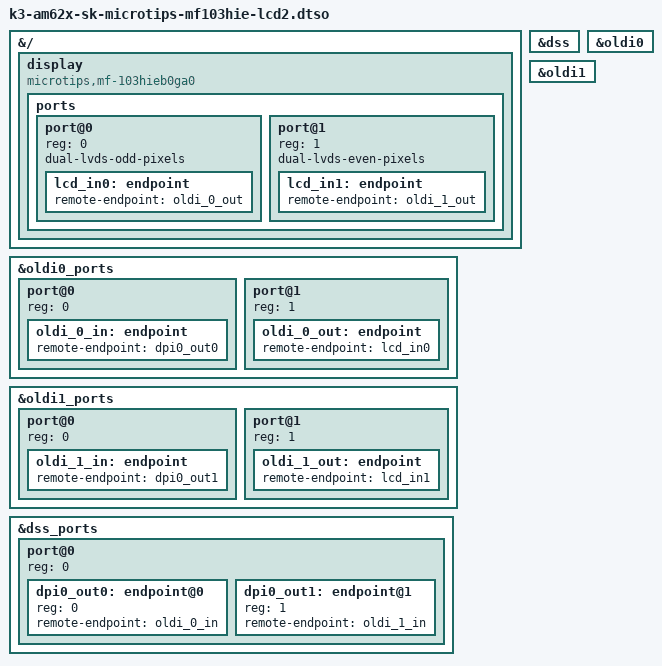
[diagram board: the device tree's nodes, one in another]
// SPDX-License-Identifier: GPL-2.0-or-later OR MIT
/**
 * Microtips integrated OLDI panel (MF-103HIEB0GA0) (SK-LCD2) DT overlay for AM625-SK and AM62-LP SK
 *
 * AM625-SKEVM: https://www.ti.com/tool/SK-AM62
 * AM62-LP SKEVM: https://www.ti.com/tool/SK-AM62-LP
 * Panel datasheet: https://simplespec.microtipsusa.com/uploads/spec/datasheetFile/2660/13-103HIEB0GA0-S_V1.0_20211206.pdf
 *
 * Copyright (C) 2024 Texas Instruments Incorporated - http://www.ti.com/
 */

/dts-v1/;
/plugin/;

#include <dt-bindings/gpio/gpio.h>
#include <dt-bindings/interrupt-controller/irq.h>

&{/} {
	display {
		compatible = "microtips,mf-103hieb0ga0", "panel-simple";
		/*
		* Note that the OLDI TX 0 transmits the odd set of pixels
		* while the OLDI TX 1 transmits the even set. This is a
		* fixed configuration in the IP integration and is not
		* changeable. The properties, "dual-lvds-odd-pixels" and
		* "dual-lvds-even-pixels" have been used to merely
		* identify if a Dual Link configuration is required.
		* Swapping them will cause an error in the dss oldi driver.
		*/
		ports {
			#address-cells = <1>;
			#size-cells = <0>;

			port@0 {
				reg = <0>;
				dual-lvds-odd-pixels;
				lcd_in0: endpoint {
					remote-endpoint = <&oldi_0_out>;
				};
			};
			port@1 {
				reg = <1>;
				dual-lvds-even-pixels;
				lcd_in1: endpoint {
					remote-endpoint = <&oldi_1_out>;
				};
			};
		};
	};
};

&dss {
	status = "okay";
};

&oldi0 {
	status = "okay";
};

&oldi1 {
	status = "okay";
};

&oldi0_ports {
	#address-cells = <1>;
	#size-cells = <0>;

	port@0 {
		reg = <0>;
		oldi_0_in: endpoint {
			remote-endpoint = <&dpi0_out0>;
		};
	};

	port@1 {
		reg = <1>;
		oldi_0_out: endpoint {
			remote-endpoint = <&lcd_in0>;
		};
	};
};

&oldi1_ports {
	#address-cells = <1>;
	#size-cells = <0>;

	port@0 {
		reg = <0>;
		oldi_1_in: endpoint {
			remote-endpoint = <&dpi0_out1>;
		};
	};

	port@1 {
		reg = <1>;
		oldi_1_out: endpoint {
			remote-endpoint = <&lcd_in1>;
		};
	};
};

&dss_ports {
	#address-cells = <1>;
	#size-cells = <0>;

	/* VP1: Output to OLDI */
	port@0 {
		reg = <0>;
		#address-cells = <1>;
		#size-cells = <0>;

		dpi0_out0: endpoint@0 {
			reg = <0>;
			remote-endpoint = <&oldi_0_in>;
		};
		dpi0_out1: endpoint@1 {
			reg = <1>;
			remote-endpoint = <&oldi_1_in>;
		};
	};
};
